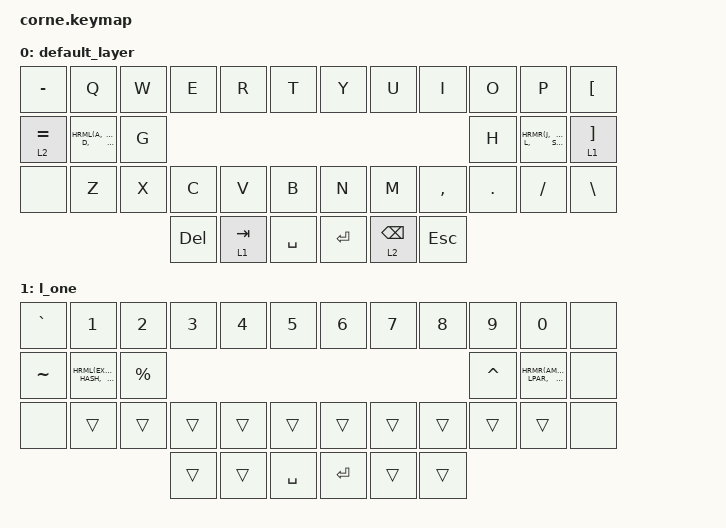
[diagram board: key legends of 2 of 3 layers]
/*
 * Copyright (c) 2020 The ZMK Contributors
 *
 * SPDX-License-Identifier: MIT
 */

#include <behaviors.dtsi>
#include <dt-bindings/zmk/keys.h>
#include <dt-bindings/zmk/bt.h>

// Home row mods macro
#define HRML(k1,k2,k3,k4) &ht LSHFT k1  &ht LCTRL k2  &ht LGUI k3   &ht LALT k4
#define HRMR(k1,k2,k3,k4) &ht RALT k1   &ht RGUI k2   &ht RCTRL k3  &ht RSHIFT k4

/ {
  behaviors {
    ht: hold_tap {
      label = "hold_tap";
      compatible = "zmk,behavior-hold-tap";
      #binding-cells = <2>;
      flavor = "tap-preferred";
      tapping-term-ms = <200>;
      quick-tap-ms = <200>;
      bindings = <&kp>, <&kp>;
    };
  };

  keymap {
    compatible = "zmk,keymap";

    default_layer {
      bindings = <
// ╭────────────┬────────────┬────────────┬────────────┬────────────┬────────────╮    ╭────────────┬────────────┬────────────┬────────────┬────────────┬────────────╮
// |  - _       |  Q         |  W         |  E         |  R         |  T         |    |  Y         |  U         | I          |  O         |  P         |  [ {       |
     &kp MINUS    &kp Q        &kp W        &kp E        &kp R       &kp T              &kp Y        &kp U        &kp I        &kp O        &kp P        &kp LEFT_BRACKET
// ├────────────┼────────────┼────────────┼────────────┼────────────┤────────────┤    ├────────────┼────────────┼────────────┼────────────┼────────────┤────────────┤
// |  = +       |  LWR/A     |  S         |  D         |  F         |  G         |    |  H         |  J         |  K         |  L         |  ; :       |  ] }       |
     &lt 2 EQUAL  HRML(A,      S,           D,           F)           &kp G             &kp H        HRMR(J,      K,           L,           SEMICOLON)   &lt 1 RIGHT_BRACKET
// ├────────────┼────────────┼────────────┼────────────┼────────────┤────────────┤    ├────────────┼────────────┼────────────┼────────────┼────────────┤────────────┤
// |            |  Z         |  X         |  C         |  V         |  B         |    |  N         |  M         |  ,         |  .         |  /         |  \ "|"     |
     &none        &kp Z        &kp X        &kp C        &kp V        &kp B             &kp N        &kp M        &kp COMMA    &kp DOT      &kp FSLH     &kp BACKSLASH
// ╰────────────┴────────────┴────────────┼────────────┼────────────┤────────────┤    ├────────────┼────────────┤────────────┤────────────┴────────────┴────────────╯
//                                        |  DEL       |  LWR       |  SPC       |    |  ENT       |  RSE       |  ESC       |
                                            &kp DEL      &lt 1 TAB    &kp SPACE         &kp RET      &lt 2 BSPC   &kp ESC
//                                        ╰────────────┴────────────┴────────────╯    ╰────────────┴────────────┴────────────╯
      >;
    };

    l_one {
      bindings = <
// ╭────────────┬────────────┬────────────┬────────────┬────────────┬────────────╮    ╭────────────┬────────────┬────────────┬────────────┬────────────┬────────────╮
// |  `         |  1         |  2         |  3         |  4         |  5         |    |  6         |  7         |  8         |  9         |  0         |            |
     &kp GRAVE    &kp N1       &kp N2       &kp N3       &kp N4       &kp N5      	   &kp N6       &kp N7       &kp N8       &kp N9       &kp N0       &none
// ├────────────┼────────────┼────────────┼────────────┼────────────┤────────────┤    ├────────────┼────────────┼────────────┼────────────┼────────────┤────────────┤
// |  ~         |  !         |  @         │  #         │  $         │  %         |    |  ^         │  &         │  *         |  (         |  )         |            |
     &kp TILDE     HRML(EXCL,  AT,           HASH,       DLLR)        &kp PRCNT         &kp CARET    HRMR(AMPS,   ASTRK,       LPAR,        RPAR)        &none
// ├────────────┼────────────┼────────────┼────────────┼────────────┤────────────┤    ├────────────┼────────────┼────────────┼────────────┼────────────┤────────────┤
// |            |            |            |            |            |            |    |            |            |            |            |            |            |
     &none        &trans       &trans       &trans       &trans       &trans      	   &trans       &trans       &trans       &trans       &trans       &none
// ╰────────────┴────────────┴────────────┼────────────┼────────────┤────────────┤    ├────────────┼────────────┤────────────┤────────────┴────────────┴────────────╯
//                                        |            |            |  SPC       |    |  ENT       |            |            |
                                            &trans       &trans       &kp SPACE         &kp RET       &trans      &trans
//                                        ╰────────────┴────────────┴────────────╯    ╰────────────┴────────────┴────────────╯
      >;
    };

    l_two {
      bindings = <
// ╭────────────┬────────────┬────────────┬────────────┬────────────┬────────────╮    ╭────────────┬────────────┬────────────┬────────────┬────────────┬────────────╮
// |  F1        |  F2        |  F3        |  F4        |  F5        |  F6        |  	 |  F7        |  F8        |  F9        |  F10       |  F11       |  F12       |
     &kp F1       &kp F2       &kp F3       &kp F4       &kp F5       &kp F6            &kp F7       &kp F8       &kp F9       &kp F10      &kp F11      &kp F12        
// ├────────────┼────────────┼────────────┼────────────┼────────────┤────────────┤    ├────────────┼────────────┼────────────┼────────────┼────────────┤────────────┤
// |            |            |            |            |            |            |    |  LFT       |  DWN       |  UP        |  RGT       |  '          |           |
     &none        &trans       &trans       &trans       &trans       &trans            &kp LEFT     HRMR(DOWN,   UP,          RIGHT,       SQT)         &none
// ├────────────┼────────────┼────────────┼────────────┼────────────┤────────────┤    ├────────────┼────────────┼────────────┼────────────┼────────────┤────────────┤
// |            |            |            |            |            |            |    |  HOME      |  PG_UP     |  PG_DN     |  END       |            |            |       
     &none        &trans       &trans       &trans       &trans       &trans            &kp HOME     &kp PG_UP    &kp PG_DN    &kp END      &trans       &none
// ╰────────────┴────────────┴────────────┼────────────┼────────────┤────────────┤    ├────────────┼────────────┤────────────┤────────────┴────────────┴────────────╯
//                                        |            |            |  SPC       |    |            |            |            |
                                            &trans        &trans      &kp SPACE         &kp RET      &trans       &trans
//                                        ╰────────────┴────────────┴────────────╯    ╰────────────┴────────────┴────────────╯
      >;
    };
  };
};
